# STM32L562 register map
File version: 1.1
Registers are 32-bit, read-write, reset 0x0 unless marked. A register's access mark holds for its fields unless they carry their own. Offsets are from the block's base; lines under a group give offsets from that group; [hi:lo] are bit positions; {n}, {i} and the like mark numbered series; 'fields as' and 'values as' point back to an identical list; <NAME> marks a mode.

## Memory map
0xE000E100 NVIC size 0x37D — Nested Vectored Interrupt Controller

## NVIC — Nested Vectored Interrupt Controller
Base 0xE000E100
{0x0+4i} ISER{i} (i=0..2) — Interrupt Set-Enable Register
  [31:0] SETENA
0x0C ISER3 — Interrupt Set-Enable Register
{0x80+4i} ICER{i} (i=0..2) — Interrupt Clear-Enable Register
  [31:0] CLRENA
0x8C ICER3 — Interrupt Clear-Enable Register
{0x100+4i} ISPR{i} (i=0..2) — Interrupt Set-Pending Register
  [31:0] SETPEND
0x10C ISPR3 — Interrupt Set-Pending Register
{0x180+4i} ICPR{i} (i=0..2) — Interrupt Clear-Pending Register
  [31:0] CLRPEND
0x18C ICPR3 — Interrupt Clear-Pending Register
{0x200+4i} IABR{i} ro (i=0..2) — Interrupt Active Bit Register
  [31:0] ACTIVE
0x20C IABR3 — Interrupt Active Bit Register
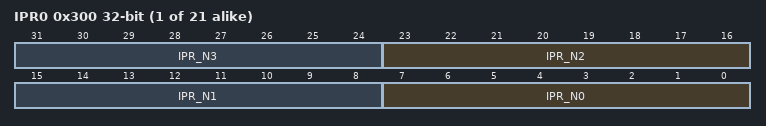
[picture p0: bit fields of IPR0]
{0x300+4i} IPR{i} (i=0..20) — Interrupt Priority Register
  [8n+7:8n] IPR_N{n} (n=0..3)
{0x300+4i} IPR{i} (i=21..29)
